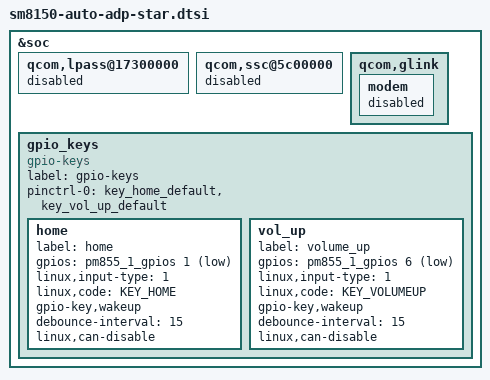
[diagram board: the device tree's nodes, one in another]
/* Copyright (c) 2018, The Linux Foundation. All rights reserved.
 *
 * This program is free software; you can redistribute it and/or modify
 * it under the terms of the GNU General Public License version 2 and
 * only version 2 as published by the Free Software Foundation.
 *
 * This program is distributed in the hope that it will be useful,
 * but WITHOUT ANY WARRANTY; without even the implied warranty of
 * MERCHANTABILITY or FITNESS FOR A PARTICULAR PURPOSE.  See the
 * GNU General Public License for more details.
 */

#include <dt-bindings/gpio/gpio.h>
#include <dt-bindings/input/input.h>

#include "sm8150-auto-pmic-overlay.dtsi"

&soc {
	qcom,lpass@17300000 {
		status = "disabled";
	};

	qcom,ssc@5c00000 {
		status = "disabled";
	};

	qcom,glink {
		modem {
			status = "disabled";
		};
	};

	gpio_keys {
		compatible = "gpio-keys";
		label = "gpio-keys";

		pinctrl-names = "default";
		pinctrl-0 = <&key_home_default
			     &key_vol_up_default>;

		home {
			label = "home";
			gpios = <&pm855_1_gpios 1 GPIO_ACTIVE_LOW>;
			linux,input-type = <1>;
			linux,code = <KEY_HOME>;
			gpio-key,wakeup;
			debounce-interval = <15>;
			linux,can-disable;
		};

		vol_up {
			label = "volume_up";
			gpios = <&pm855_1_gpios 6 GPIO_ACTIVE_LOW>;
			linux,input-type = <1>;
			linux,code = <KEY_VOLUMEUP>;
			gpio-key,wakeup;
			debounce-interval = <15>;
			linux,can-disable;
		};
	};
};
